# ipro7 register map
Vendor: intelpro; Series: BTBLE
CPU: ipro7, little endian
Registers are 32-bit, read-write, reset 0x0 unless marked. A register's access mark holds for its fields unless they carry their own. Offsets are from the block's base; [hi:lo] are bit positions; {n}, {i} and the like mark numbered series; 'fields as' and 'values as' point back to an identical list.

## PWM
Base 0x3000F000
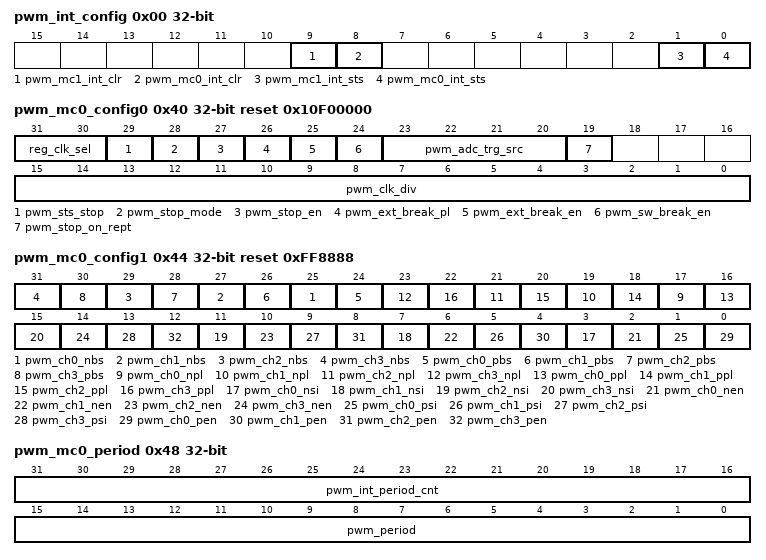
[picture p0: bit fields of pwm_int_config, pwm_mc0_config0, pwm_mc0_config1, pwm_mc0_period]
0x00 pwm_int_config (reset mask 0xFFFFFFFC)
  [9] pwm_mc1_int_clr — PWM_MC1 interrupt clear (clear pwm_mc1_int_sts[10:0] all)
  [8] pwm_mc0_int_clr — PWM_MC0 interrupt clear (clear pwm_mc0_int_sts[10:0] all)
  [1] pwm_mc1_int_sts ro — PWM_MC1 interrupt status (Check pwm_mc1_int_sts for detailed interrupt status)
  [0] pwm_mc0_int_sts ro — PWM_MC0 interrupt status (Check pwm_mc0_int_sts for detailed interrupt status)
0x40 pwm_mc0_config0 reset 0x10F00000 (reset mask 0xDFFFFFFF)
  [31:30] reg_clk_sel — PWM clock source select, 2'b00-xclk ; 2'b01-bclk ; others-f32k_clk
  [29] pwm_sts_stop ro — PWM stop status
  [28] pwm_stop_mode — PWM stop mode, 1'b1 - graceful ; 1'b0 - abrupt
  [27] pwm_stop_en — PWM stop enable
  [26] pwm_ext_break_pl — PWM external break source polarity 1'b0: Active-LOW 1'b1: Active-HIGH
  [25] pwm_ext_break_en — PWM external break source enable 1'b0: Disabled, external break signal is masked 1'b1: Enabled, external break signal is effective
  [24] pwm_sw_break_en — PWM break enable 1'b0: Disabled, normal operation 1'b1: Enabled, PWM output will be determined by CxPBS/CxNBS
  [23:20] pwm_adc_trg_src — Select signal of ADC triggering source 4'd0: pwm_ch0l_int (Channel 0 ThresholdL reached) 4'd1: pwm_ch0h_int (Channel 0 ThresholdH reached) 4'd2: pwm_ch1l_int (Channel 1 ThresholdL reached) 4'd3: pwm_ch1h_int (Channel 1 ThresholdH reached) 4'd4: pwm_ch2l_int (Channel 2 ThresholdL reached) 4'd5: pwm_ch2h_int (Channel 2 ThresholdH reached) 4'd6: pwm_ch3l_int (Channel 3 ThresholdL reached) 4'd7: pwm_ch3h_int (Channel 3 ThresholdH reached) 4'd8: pwm_prde_int (Period End reached) Others: Disabled
  [19] pwm_stop_on_rept — PWM stopped when rept_int is asserted 1'b0: Disabled, PWM keeps running when rept_int is asserted 1'b1: Enabled, PWM stops when rept_int is asserted. Clear rept_int to restore operation
  [15:0] pwm_clk_div — PWM clock division
0x44 pwm_mc0_config1 reset 0xFF8888
  [2n+25] pwm_ch{n}_nbs (n=0..3) — PWM channel {n} negative break state
  [2n+24] pwm_ch{n}_pbs (n=0..3) — PWM channel {n} positive break state
  [2n+17] pwm_ch{n}_npl (n=0..3) — PWM channel {n} negative polarity
  [2n+16] pwm_ch{n}_ppl (n=0..3) — PWM channel {n} positive polarity
  [4n+3] pwm_ch{n}_nsi (n=0..3) — PWM channel {n} negative set idle state
  [4n+2] pwm_ch{n}_nen (n=0..3) — PWM channel {n} negative enable pwm out
  [4n+1] pwm_ch{n}_psi (n=0..3) — PWM channel {n} positive set idle state
  [4n] pwm_ch{n}_pen (n=0..3) — PWM channel {n} positive enable pwm out
0x48 pwm_mc0_period
  [31:16] pwm_int_period_cnt — PWM interrupt period counter threshold
  [15:0] pwm_period — PWM period setting
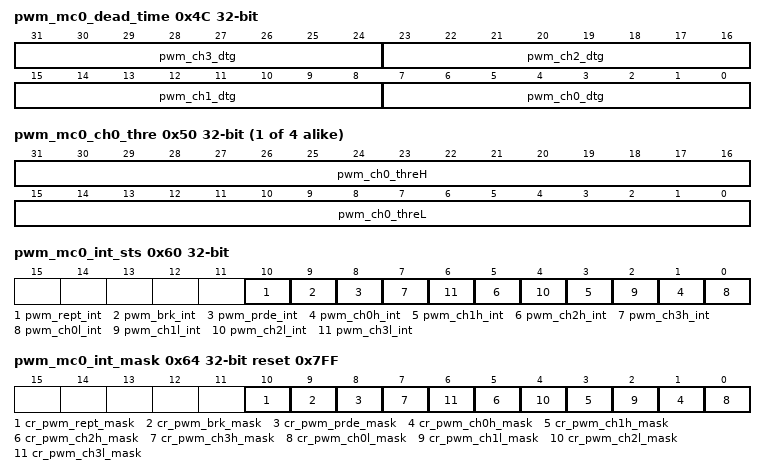
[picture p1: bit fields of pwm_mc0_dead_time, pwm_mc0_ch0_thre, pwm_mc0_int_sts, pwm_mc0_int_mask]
0x4C pwm_mc0_dead_time
  [8n+7:8n] pwm_ch{n}_dtg (n=0..3) — PWM Channel {n} dead time generator (DTG) DTG[7:5]=0xx => DT = DTG[7:0]*1 (unit: divided PWM clock) DTG[7:5]=10x => DT = (64+DTG[5:0])*2 (unit: divided PWM clock) DTG[7:5]=110 => DT = (32+DTG[4:0])*8 (unit: divided PWM clock) DTG[7:5]=111 => DT = (32+DTG[4:0])*16 (unit: divided PWM clock)
{0x50+4i} pwm_mc0_ch{i}_thre (i=0..3)
  [31:16] pwm_ch{i}_threH — PWM HIGH counter threshold, can't be smaller that threL
  [15:0] pwm_ch{i}_threL — PWM LOW counter threshold, can't be larger that threH
0x60 pwm_mc0_int_sts (reset mask 0xFFFFF800)
  [10] pwm_rept_int ro — PWM repeat count interrupt status
  [9] pwm_brk_int ro — PWM break interrupt status, triggered when ext_break is asserted Note: pwm_sw_break_en will NOT trigger this interrupt
  [8] pwm_prde_int ro — PWM period end interrupt status
  [2n+1] pwm_ch{n}h_int ro (n=0..3) — PWM Channel {n} ThresholdH interrupt status
  [2n] pwm_ch{n}l_int ro (n=0..3) — PWM Channel {n} ThresholdL interrupt status
0x64 pwm_mc0_int_mask reset 0x7FF
  [10] cr_pwm_rept_mask — Interrupt mask of pwm_rept_int
  [9] cr_pwm_brk_mask — Interrupt mask of pwm_brk_int
  [8] cr_pwm_prde_mask — Interrupt mask of pwm_prde_int
  [2n+1] cr_pwm_ch{n}h_mask (n=0..3) — Interrupt mask of pwm_ch{n}h_int
  [2n] cr_pwm_ch{n}l_mask (n=0..3) — Interrupt mask of pwm_ch{n}l_int
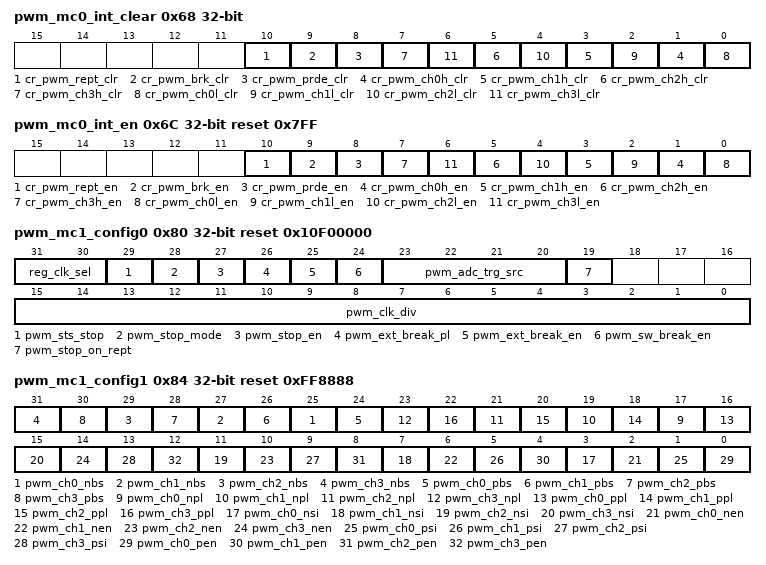
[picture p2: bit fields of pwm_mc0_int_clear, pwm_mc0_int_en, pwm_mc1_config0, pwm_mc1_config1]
0x68 pwm_mc0_int_clear
  [10] cr_pwm_rept_clr — Interrupt clear of pwm_rept_int
  [9] cr_pwm_brk_clr — Interrupt clear of pwm_brk_int
  [8] cr_pwm_prde_clr — Interrupt clear of pwm_prde_int
  [2n+1] cr_pwm_ch{n}h_clr (n=0..3) — Interrupt clear of pwm_ch{n}h_int
  [2n] cr_pwm_ch{n}l_clr (n=0..3) — Interrupt clear of pwm_ch{n}l_int
0x6C pwm_mc0_int_en reset 0x7FF
  [10] cr_pwm_rept_en — Interrupt enable of pwm_rept_int
  [9] cr_pwm_brk_en — Interrupt enable of pwm_brk_int
  [8] cr_pwm_prde_en — Interrupt enable of pwm_prde_int
  [2n+1] cr_pwm_ch{n}h_en (n=0..3) — Interrupt enable of pwm_ch{n}h_int
  [2n] cr_pwm_ch{n}l_en (n=0..3) — Interrupt enable of pwm_ch{n}l_int
0x80 pwm_mc1_config0 reset 0x10F00000 (reset mask 0xDFFFFFFF)
  fields as pwm_mc0_config0
0x84 pwm_mc1_config1 reset 0xFF8888
  fields as pwm_mc0_config1
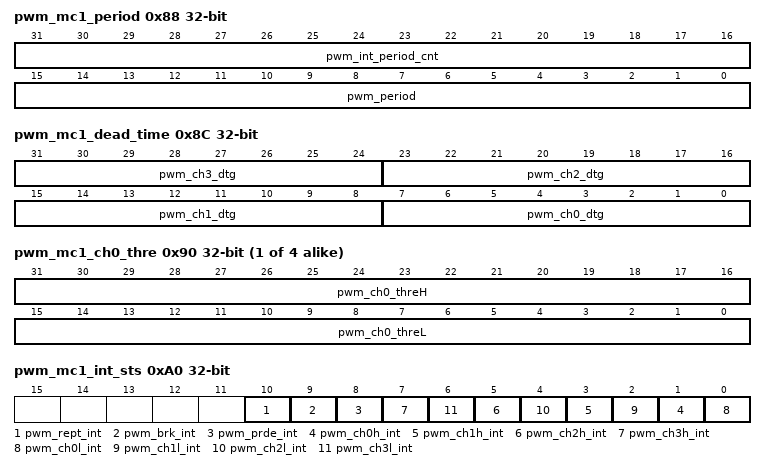
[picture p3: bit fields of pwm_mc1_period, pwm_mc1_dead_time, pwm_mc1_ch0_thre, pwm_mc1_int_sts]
0x88 pwm_mc1_period
  fields as pwm_mc0_period
0x8C pwm_mc1_dead_time
  fields as pwm_mc0_dead_time
{0x90+4i} pwm_mc1_ch{i}_thre (i=0..3)
  fields as pwm_mc0_ch0_thre
0xA0 pwm_mc1_int_sts (reset mask 0xFFFFF800)
  fields as pwm_mc0_int_sts
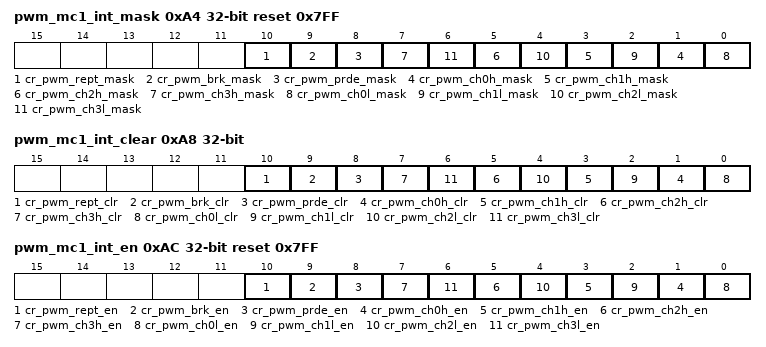
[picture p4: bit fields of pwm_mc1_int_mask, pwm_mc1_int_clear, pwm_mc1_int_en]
0xA4 pwm_mc1_int_mask reset 0x7FF
  fields as pwm_mc0_int_mask
0xA8 pwm_mc1_int_clear
  fields as pwm_mc0_int_clear
0xAC pwm_mc1_int_en reset 0x7FF
  fields as pwm_mc0_int_en
